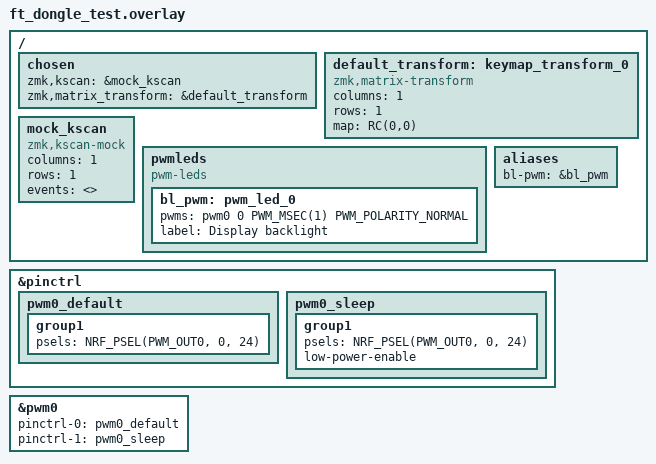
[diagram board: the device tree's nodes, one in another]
/*
 * FT Dongle Test - minimalny shield do testu PWM backlight
 * BL backlight -> nice!nano D5 / P0.24 / PWM0 OUT0
 */

#include <dt-bindings/zmk/matrix_transform.h>
#include <zephyr/dt-bindings/pinctrl/nrf-pinctrl.h>
#include <zephyr/dt-bindings/pwm/pwm.h>

/ {
    chosen {
        zmk,kscan = &mock_kscan;
        zmk,matrix_transform = &default_transform;
    };

    default_transform: keymap_transform_0 {
        compatible = "zmk,matrix-transform";
        columns = <1>;
        rows = <1>;
        map = <RC(0,0)>;
    };

    mock_kscan: mock_kscan {
        compatible = "zmk,kscan-mock";
        columns = <1>;
        rows = <1>;
        events = <>;
    };

    pwmleds: pwmleds {
        compatible = "pwm-leds";
        bl_pwm: pwm_led_0 {
            pwms = <&pwm0 0 PWM_MSEC(1) PWM_POLARITY_NORMAL>;
            label = "Display backlight";
        };
    };

    aliases {
        bl-pwm = &bl_pwm;
    };
};

&pinctrl {
    pwm0_default: pwm0_default {
        group1 {
            psels = <NRF_PSEL(PWM_OUT0, 0, 24)>;
        };
    };

    pwm0_sleep: pwm0_sleep {
        group1 {
            psels = <NRF_PSEL(PWM_OUT0, 0, 24)>;
            low-power-enable;
        };
    };
};

&pwm0 {
    status = "okay";
    pinctrl-0 = <&pwm0_default>;
    pinctrl-1 = <&pwm0_sleep>;
    pinctrl-names = "default", "sleep";
};
